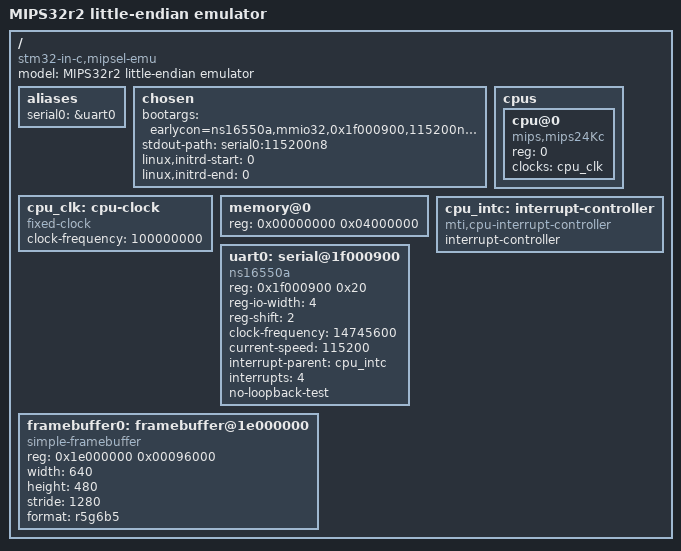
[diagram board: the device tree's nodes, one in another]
// SPDX-License-Identifier: GPL-2.0-only
/dts-v1/;

/* The loader places the UHI DTB at physical address 0x00010000. */
/memreserve/ 0x00010000 0x00010000;

/ {
	#address-cells = <1>;
	#size-cells = <1>;
	compatible = "stm32-in-c,mipsel-emu";
	model = "MIPS32r2 little-endian emulator";

	aliases {
		serial0 = &uart0;
	};

	chosen {
		/* Explicit MMIO32 earlycon is available before the 8250 platform driver. */
		/* ttyS0 remains last so it is the controlling console for init. */
		bootargs = "earlycon=ns16550a,mmio32,0x1f000900,115200n8 console=tty0 console=ttyS0,115200n8 ignore_loglevel";
		stdout-path = "serial0:115200n8";
		/* Fixed-width placeholders patched by the portable image loader. */
		linux,initrd-start = <0>;
		linux,initrd-end = <0>;
	};

	cpus {
		#address-cells = <1>;
		#size-cells = <0>;

		cpu@0 {
			device_type = "cpu";
			compatible = "mips,mips24Kc";
			reg = <0>;
			clocks = <&cpu_clk>;
		};
	};

	cpu_clk: cpu-clock {
		compatible = "fixed-clock";
		#clock-cells = <0>;
		/* The MIPS Count clock is half this 100 MHz CPU clock. */
		clock-frequency = <100000000>;
	};

	memory@0 {
		device_type = "memory";
		reg = <0x00000000 0x04000000>;
	};

	cpu_intc: interrupt-controller {
		compatible = "mti,cpu-interrupt-controller";
		interrupt-controller;
		#address-cells = <0>;
		#interrupt-cells = <1>;
	};

	uart0: serial@1f000900 {
		compatible = "ns16550a";
		reg = <0x1f000900 0x20>;
		reg-io-width = <4>;
		reg-shift = <2>;
		clock-frequency = <14745600>;
		current-speed = <115200>;
		interrupt-parent = <&cpu_intc>;
		interrupts = <4>;
		no-loopback-test;
		status = "okay";
	};

	framebuffer0: framebuffer@1e000000 {
		compatible = "simple-framebuffer";
		reg = <0x1e000000 0x00096000>;
		width = <640>;
		height = <480>;
		stride = <1280>;
		format = "r5g6b5";
		status = "okay";
	};
};
